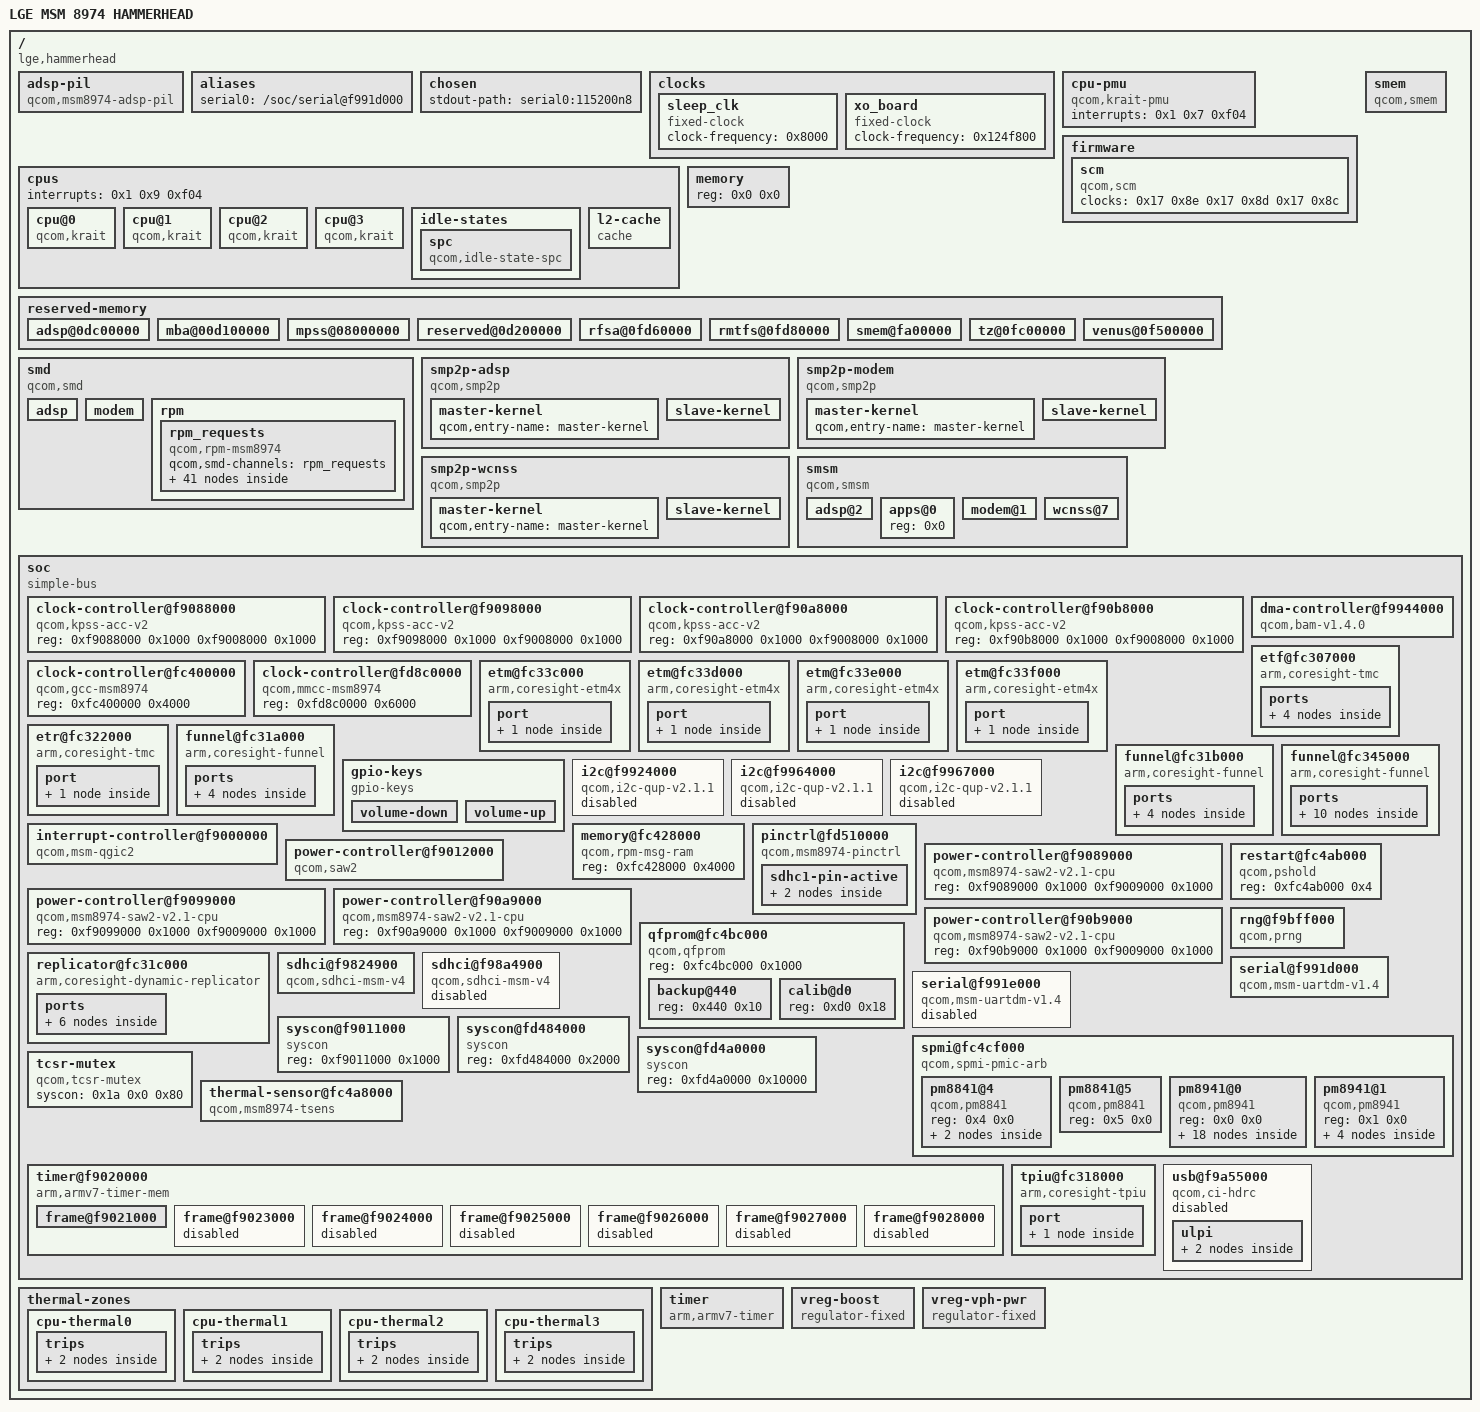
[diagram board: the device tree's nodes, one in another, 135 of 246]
/dts-v1/;

/ {
	#address-cells = <0x1>;
	#size-cells = <0x1>;
	compatible = "lge,hammerhead", "qcom,msm8974";
	interrupt-parent = <0x1>;
	model = "LGE MSM 8974 HAMMERHEAD";

	__symbols__ {
		CPU0 = "/cpus/cpu@0";
		CPU1 = "/cpus/cpu@1";
		CPU2 = "/cpus/cpu@2";
		CPU3 = "/cpus/cpu@3";
		CPU_SPC = "/cpus/idle-states/spc";
		L2 = "/cpus/l2-cache";
		acc0 = "/soc/clock-controller@f9088000";
		acc1 = "/soc/clock-controller@f9098000";
		acc2 = "/soc/clock-controller@f90a8000";
		acc3 = "/soc/clock-controller@f90b8000";
		adsp_region = "/reserved-memory/adsp@0dc00000";
		adsp_smp2p_in = "/smp2p-adsp/slave-kernel";
		adsp_smp2p_out = "/smp2p-adsp/master-kernel";
		adsp_smsm = "/smsm/adsp@2";
		apcs = "/soc/syscon@f9011000";
		apps_smsm = "/smsm/apps@0";
		blsp1_uart1 = "/soc/serial@f991d000";
		blsp1_uart2 = "/soc/serial@f991e000";
		blsp2_dma = "/soc/dma-controller@f9944000";
		blsp_i2c11 = "/soc/i2c@f9967000";
		blsp_i2c8 = "/soc/i2c@f9964000";
		boost_bypass_n_pin = "/soc/spmi@fc4cf000/pm8941@0/gpios@c000/boost-bypass";
		chg_otg = "/soc/spmi@fc4cf000/pm8941@0/charger@1000/otg-vbus";
		cpu_alert0 = "/thermal-zones/cpu-thermal0/trips/trip0";
		cpu_alert1 = "/thermal-zones/cpu-thermal1/trips/trip0";
		cpu_alert2 = "/thermal-zones/cpu-thermal2/trips/trip0";
		cpu_alert3 = "/thermal-zones/cpu-thermal3/trips/trip0";
		cpu_crit0 = "/thermal-zones/cpu-thermal0/trips/trip1";
		cpu_crit1 = "/thermal-zones/cpu-thermal1/trips/trip1";
		cpu_crit2 = "/thermal-zones/cpu-thermal2/trips/trip1";
		cpu_crit3 = "/thermal-zones/cpu-thermal3/trips/trip1";
		etf_in = "/soc/etf@fc307000/ports/port@1/endpoint";
		etf_out = "/soc/etf@fc307000/ports/port@0/endpoint";
		etm0_out = "/soc/etm@fc33c000/port/endpoint";
		etm1_out = "/soc/etm@fc33d000/port/endpoint";
		etm2_out = "/soc/etm@fc33e000/port/endpoint";
		etm3_out = "/soc/etm@fc33f000/port/endpoint";
		etr_in = "/soc/etr@fc322000/port/endpoint";
		funnel1_in5 = "/soc/funnel@fc31a000/ports/port@5/endpoint";
		funnel1_out = "/soc/funnel@fc31a000/ports/port@8/endpoint";
		gcc = "/soc/clock-controller@fc400000";
		gpio_keys_pin_a = "/soc/spmi@fc4cf000/pm8941@0/gpios@c000/gpio-keys-active";
		intc = "/soc/interrupt-controller@f9000000";
		kpss_in0 = "/soc/funnel@fc345000/ports/port@0/endpoint";
		kpss_in1 = "/soc/funnel@fc345000/ports/port@1/endpoint";
		kpss_in2 = "/soc/funnel@fc345000/ports/port@2/endpoint";
		kpss_in3 = "/soc/funnel@fc345000/ports/port@3/endpoint";
		kpss_out = "/soc/funnel@fc345000/ports/port@8/endpoint";
		merger_in1 = "/soc/funnel@fc31b000/ports/port@1/endpoint";
		merger_out = "/soc/funnel@fc31b000/ports/port@8/endpoint";
		mmcc = "/soc/clock-controller@fd8c0000";
		modem_smp2p_in = "/smp2p-modem/slave-kernel";
		modem_smp2p_out = "/smp2p-modem/master-kernel";
		modem_smsm = "/smsm/modem@1";
		msmgpio = "/soc/pinctrl@fd510000";
		otg = "/soc/usb@f9a55000";
		pm8841_0 = "/soc/spmi@fc4cf000/pm8841@4";
		pm8841_1 = "/soc/spmi@fc4cf000/pm8841@5";
		pm8841_mpps = "/soc/spmi@fc4cf000/pm8841@4/mpps@a000";
		pm8841_s1 = "/smd/rpm/rpm_requests/pm8841-regulators/s1";
		pm8841_s2 = "/smd/rpm/rpm_requests/pm8841-regulators/s2";
		pm8841_s3 = "/smd/rpm/rpm_requests/pm8841-regulators/s3";
		pm8841_s4 = "/smd/rpm/rpm_requests/pm8841-regulators/s4";
		pm8841_s5 = "/smd/rpm/rpm_requests/pm8841-regulators/s5";
		pm8841_s6 = "/smd/rpm/rpm_requests/pm8841-regulators/s6";
		pm8841_s7 = "/smd/rpm/rpm_requests/pm8841-regulators/s7";
		pm8841_s8 = "/smd/rpm/rpm_requests/pm8841-regulators/s8";
		pm8941_0 = "/soc/spmi@fc4cf000/pm8941@0";
		pm8941_1 = "/soc/spmi@fc4cf000/pm8941@1";
		pm8941_5v = "/soc/spmi@fc4cf000/pm8941@1/regulators/s4";
		pm8941_5vs1 = "/soc/spmi@fc4cf000/pm8941@1/regulators/5vs1";
		pm8941_gpios = "/soc/spmi@fc4cf000/pm8941@0/gpios@c000";
		pm8941_iadc = "/soc/spmi@fc4cf000/pm8941@0/iadc@3600";
		pm8941_l1 = "/smd/rpm/rpm_requests/pm8941-regulators/l1";
		pm8941_l10 = "/smd/rpm/rpm_requests/pm8941-regulators/l10";
		pm8941_l11 = "/smd/rpm/rpm_requests/pm8941-regulators/l11";
		pm8941_l12 = "/smd/rpm/rpm_requests/pm8941-regulators/l12";
		pm8941_l13 = "/smd/rpm/rpm_requests/pm8941-regulators/l13";
		pm8941_l14 = "/smd/rpm/rpm_requests/pm8941-regulators/l14";
		pm8941_l15 = "/smd/rpm/rpm_requests/pm8941-regulators/l15";
		pm8941_l16 = "/smd/rpm/rpm_requests/pm8941-regulators/l16";
		pm8941_l17 = "/smd/rpm/rpm_requests/pm8941-regulators/l17";
		pm8941_l18 = "/smd/rpm/rpm_requests/pm8941-regulators/l18";
		pm8941_l19 = "/smd/rpm/rpm_requests/pm8941-regulators/l19";
		pm8941_l2 = "/smd/rpm/rpm_requests/pm8941-regulators/l2";
		pm8941_l20 = "/smd/rpm/rpm_requests/pm8941-regulators/l20";
		pm8941_l21 = "/smd/rpm/rpm_requests/pm8941-regulators/l21";
		pm8941_l22 = "/smd/rpm/rpm_requests/pm8941-regulators/l22";
		pm8941_l23 = "/smd/rpm/rpm_requests/pm8941-regulators/l23";
		pm8941_l24 = "/smd/rpm/rpm_requests/pm8941-regulators/l24";
		pm8941_l3 = "/smd/rpm/rpm_requests/pm8941-regulators/l3";
		pm8941_l4 = "/smd/rpm/rpm_requests/pm8941-regulators/l4";
		pm8941_l5 = "/smd/rpm/rpm_requests/pm8941-regulators/l5";
		pm8941_l6 = "/smd/rpm/rpm_requests/pm8941-regulators/l6";
		pm8941_l7 = "/smd/rpm/rpm_requests/pm8941-regulators/l7";
		pm8941_l8 = "/smd/rpm/rpm_requests/pm8941-regulators/l8";
		pm8941_l9 = "/smd/rpm/rpm_requests/pm8941-regulators/l9";
		pm8941_lvs1 = "/smd/rpm/rpm_requests/pm8941-regulators/lvs1";
		pm8941_lvs2 = "/smd/rpm/rpm_requests/pm8941-regulators/lvs2";
		pm8941_lvs3 = "/smd/rpm/rpm_requests/pm8941-regulators/lvs3";
		pm8941_mpps = "/soc/spmi@fc4cf000/pm8941@0/mpps@a000";
		pm8941_s1 = "/smd/rpm/rpm_requests/pm8941-regulators/s1";
		pm8941_s2 = "/smd/rpm/rpm_requests/pm8941-regulators/s2";
		pm8941_s3 = "/smd/rpm/rpm_requests/pm8941-regulators/s3";
		pm8941_temp = "/soc/spmi@fc4cf000/pm8941@0/temp-alarm@2400";
		pm8941_vadc = "/soc/spmi@fc4cf000/pm8941@0/vadc@3100";
		pm8941_wled = "/soc/spmi@fc4cf000/pm8941@1/wled@d800";
		qfprom = "/soc/qfprom@fc4bc000";
		replicator_in = "/soc/replicator@fc31c000/ports/port@2/endpoint";
		replicator_out0 = "/soc/replicator@fc31c000/ports/port@0/endpoint";
		replicator_out1 = "/soc/replicator@fc31c000/ports/port@1/endpoint";
		rpm_msg_ram = "/soc/memory@fc428000";
		rpmcc = "/smd/rpm/rpm_requests/clock-controller";
		saw0 = "/soc/power-controller@f9089000";
		saw1 = "/soc/power-controller@f9099000";
		saw2 = "/soc/power-controller@f90a9000";
		saw3 = "/soc/power-controller@f90b9000";
		saw_l2 = "/soc/power-controller@f9012000";
		sdhc1_pin_a = "/soc/pinctrl@fd510000/sdhc1-pin-active";
		sleep_clk = "/clocks/sleep_clk";
		smbb = "/soc/spmi@fc4cf000/pm8941@0/charger@1000";
		smem_region = "/reserved-memory/smem@fa00000";
		soc = "/soc";
		spmi_bus = "/soc/spmi@fc4cf000";
		tcsr = "/soc/syscon@fd4a0000";
		tcsr_mutex = "/soc/tcsr-mutex";
		tcsr_mutex_block = "/soc/syscon@fd484000";
		tpiu_in = "/soc/tpiu@fc318000/port/endpoint";
		tsens = "/soc/thermal-sensor@fc4a8000";
		tsens_backup = "/soc/qfprom@fc4bc000/backup@440";
		tsens_calib = "/soc/qfprom@fc4bc000/calib@d0";
		usb_hs1_phy = "/soc/usb@f9a55000/ulpi/phy@a";
		usb_hs2_phy = "/soc/usb@f9a55000/ulpi/phy@b";
		usb_id = "/soc/spmi@fc4cf000/pm8941@0/misc@900";
		vreg_boost = "/vreg-boost";
		vreg_vph_pwr = "/vreg-vph-pwr";
		wcnss_smp2p_in = "/smp2p-wcnss/slave-kernel";
		wcnss_smp2p_out = "/smp2p-wcnss/master-kernel";
		wcnss_smsm = "/smsm/wcnss@7";
		xo_board = "/clocks/xo_board";
	};

	adsp-pil {
		clock-names = "xo";
		clocks = <0x10>;
		compatible = "qcom,msm8974-adsp-pil";
		cx-supply = <0xf>;
		interrupt-names = "wdog", "fatal", "ready", "handover", "stop-ack";
		interrupts-extended = <0x1 0x0 0xa2 0x1 0xe 0x0 0x1 0xe 0x1 0x1 0xe 0x2 0x1 0xe 0x3 0x1>;
		memory-region = <0x11>;
		qcom,smem-state-names = "stop";
		qcom,smem-states = <0x12 0x0>;
	};

	aliases {
		serial0 = "/soc/serial@f991d000";
	};

	chosen {
		stdout-path = "serial0:115200n8";
	};

	clocks {

		sleep_clk {
			#clock-cells = <0x0>;
			clock-frequency = <0x8000>;
			compatible = "fixed-clock";
			linux,phandle = <0x4b>;
			phandle = <0x4b>;
		};

		xo_board {
			#clock-cells = <0x0>;
			clock-frequency = <0x124f800>;
			compatible = "fixed-clock";
			linux,phandle = <0x10>;
			phandle = <0x10>;
		};
	};

	cpu-pmu {
		compatible = "qcom,krait-pmu";
		interrupts = <0x1 0x7 0xf04>;
	};

	cpus {
		#address-cells = <0x1>;
		#size-cells = <0x0>;
		interrupts = <0x1 0x9 0xf04>;

		cpu@0 {
			compatible = "qcom,krait";
			cpu-idle-states = <0x5>;
			device_type = "cpu";
			enable-method = "qcom,kpss-acc-v2";
			linux,phandle = <0x34>;
			next-level-cache = <0x2>;
			phandle = <0x34>;
			qcom,acc = <0x3>;
			qcom,saw = <0x4>;
			reg = <0x0>;
		};

		cpu@1 {
			compatible = "qcom,krait";
			cpu-idle-states = <0x5>;
			device_type = "cpu";
			enable-method = "qcom,kpss-acc-v2";
			linux,phandle = <0x36>;
			next-level-cache = <0x2>;
			phandle = <0x36>;
			qcom,acc = <0x6>;
			qcom,saw = <0x7>;
			reg = <0x1>;
		};

		cpu@2 {
			compatible = "qcom,krait";
			cpu-idle-states = <0x5>;
			device_type = "cpu";
			enable-method = "qcom,kpss-acc-v2";
			linux,phandle = <0x38>;
			next-level-cache = <0x2>;
			phandle = <0x38>;
			qcom,acc = <0x8>;
			qcom,saw = <0x9>;
			reg = <0x2>;
		};

		cpu@3 {
			compatible = "qcom,krait";
			cpu-idle-states = <0x5>;
			device_type = "cpu";
			enable-method = "qcom,kpss-acc-v2";
			linux,phandle = <0x3a>;
			next-level-cache = <0x2>;
			phandle = <0x3a>;
			qcom,acc = <0xa>;
			qcom,saw = <0xb>;
			reg = <0x3>;
		};

		idle-states {

			spc {
				compatible = "qcom,idle-state-spc", "arm,idle-state";
				entry-latency-us = <0x96>;
				exit-latency-us = <0xc8>;
				linux,phandle = <0x5>;
				min-residency-us = <0x7d0>;
				phandle = <0x5>;
			};
		};

		l2-cache {
			cache-level = <0x2>;
			compatible = "cache";
			linux,phandle = <0x2>;
			phandle = <0x2>;
			qcom,saw = <0xc>;
		};
	};

	firmware {

		scm {
			clock-names = "core", "bus", "iface";
			clocks = <0x17 0x8e 0x17 0x8d 0x17 0x8c>;
			compatible = "qcom,scm";
		};
	};

	memory {
		device_type = "memory";
		reg = <0x0 0x0>;
	};

	reserved-memory {
		#address-cells = <0x1>;
		#size-cells = <0x1>;
		ranges;

		adsp@0dc00000 {
			linux,phandle = <0x11>;
			no-map;
			phandle = <0x11>;
			reg = <0xdc00000 0x1900000>;
		};

		mba@00d100000 {
			no-map;
			reg = <0xd100000 0x100000>;
		};

		mpss@08000000 {
			no-map;
			reg = <0x8000000 0x5100000>;
		};

		reserved@0d200000 {
			no-map;
			reg = <0xd200000 0xa00000>;
		};

		rfsa@0fd60000 {
			no-map;
			reg = <0xfd60000 0x20000>;
		};

		rmtfs@0fd80000 {
			no-map;
			reg = <0xfd80000 0x180000>;
		};

		smem@fa00000 {
			linux,phandle = <0x13>;
			no-map;
			phandle = <0x13>;
			reg = <0xfa00000 0x200000>;
		};

		tz@0fc00000 {
			no-map;
			reg = <0xfc00000 0x160000>;
		};

		venus@0f500000 {
			no-map;
			reg = <0xf500000 0x500000>;
		};
	};

	smd {
		compatible = "qcom,smd";

		adsp {
			interrupts = <0x0 0x9c 0x1>;
			qcom,ipc = <0x16 0x8 0x8>;
			qcom,smd-edge = <0x1>;
		};

		modem {
			interrupts = <0x0 0x19 0x1>;
			qcom,ipc = <0x16 0x8 0xc>;
			qcom,smd-edge = <0x0>;
		};

		rpm {
			interrupts = <0x0 0xa8 0x1>;
			qcom,ipc = <0x16 0x8 0x0>;
			qcom,smd-edge = <0xf>;

			rpm_requests {
				compatible = "qcom,rpm-msm8974";
				qcom,smd-channels = "rpm_requests";

				clock-controller {
					#clock-cells = <0x1>;
					compatible = "qcom,rpmcc-msm8974", "qcom,rpmcc";
					linux,phandle = <0x23>;
					phandle = <0x23>;
				};

				pm8841-regulators {
					compatible = "qcom,rpm-pm8841-regulators";

					s1 {
						linux,phandle = <0x6c>;
						phandle = <0x6c>;
						regulator-max-microvolt = <0x100590>;
						regulator-min-microvolt = <0xa4cb8>;
					};

					s2 {
						linux,phandle = <0xf>;
						phandle = <0xf>;
						regulator-max-microvolt = <0x100590>;
						regulator-min-microvolt = <0x7a120>;
					};

					s3 {
						linux,phandle = <0x6d>;
						phandle = <0x6d>;
						regulator-max-microvolt = <0x100590>;
						regulator-min-microvolt = <0x100590>;
					};

					s4 {
						linux,phandle = <0x6e>;
						phandle = <0x6e>;
						regulator-max-microvolt = <0xdbba0>;
						regulator-min-microvolt = <0xc6f98>;
					};

					s5 {
						linux,phandle = <0x6f>;
						phandle = <0x6f>;
					};

					s6 {
						linux,phandle = <0x70>;
						phandle = <0x70>;
					};

					s7 {
						linux,phandle = <0x71>;
						phandle = <0x71>;
					};

					s8 {
						linux,phandle = <0x72>;
						phandle = <0x72>;
					};
				};

				pm8941-regulators {
					compatible = "qcom,rpm-pm8941-regulators";
					vdd_l13_l20_l23_l24-supply = <0x41>;
					vdd_l1_l3-supply = <0x3e>;
					vdd_l21-supply = <0x41>;
					vdd_l2_lvs1_2_3-supply = <0x1c>;
					vdd_l4_l11-supply = <0x3e>;
					vdd_l5_l7-supply = <0x3f>;
					vdd_l6_l12_l14_l15-supply = <0x3f>;
					vdd_l8_l16_l18_l19-supply = <0x40>;
					vdd_l9_l10_l17_l22-supply = <0x41>;

					l1 {
						linux,phandle = <0x73>;
						phandle = <0x73>;
						regulator-always-on;
						regulator-boot-on;
						regulator-max-microvolt = <0x12b128>;
						regulator-min-microvolt = <0x12b128>;
					};

					l10 {
						linux,phandle = <0x7c>;
						phandle = <0x7c>;
						regulator-max-microvolt = <0x2d0370>;
						regulator-min-microvolt = <0x1b7740>;
					};

					l11 {
						linux,phandle = <0x7d>;
						phandle = <0x7d>;
						regulator-max-microvolt = <0x13d620>;
						regulator-min-microvolt = <0x13d620>;
					};

					l12 {
						linux,phandle = <0x7e>;
						phandle = <0x7e>;
						regulator-always-on;
						regulator-boot-on;
						regulator-max-microvolt = <0x1b7740>;
						regulator-min-microvolt = <0x1b7740>;
					};

					l13 {
						linux,phandle = <0x7f>;
						phandle = <0x7f>;
						regulator-boot-on;
						regulator-max-microvolt = <0x2d0370>;
						regulator-min-microvolt = <0x1b7740>;
					};

					l14 {
						linux,phandle = <0x80>;
						phandle = <0x80>;
						regulator-max-microvolt = <0x1b7740>;
						regulator-min-microvolt = <0x1b7740>;
					};

					l15 {
						linux,phandle = <0x81>;
						phandle = <0x81>;
						regulator-max-microvolt = <0x1f47d0>;
						regulator-min-microvolt = <0x1f47d0>;
					};

					l16 {
						linux,phandle = <0x82>;
						phandle = <0x82>;
						regulator-max-microvolt = <0x2932e0>;
						regulator-min-microvolt = <0x2932e0>;
					};

					l17 {
						linux,phandle = <0x83>;
						phandle = <0x83>;
						regulator-max-microvolt = <0x2b7cd0>;
						regulator-min-microvolt = <0x2b7cd0>;
					};

					l18 {
						linux,phandle = <0x84>;
						phandle = <0x84>;
						regulator-max-microvolt = <0x2b7cd0>;
						regulator-min-microvolt = <0x2b7cd0>;
					};

					l19 {
						linux,phandle = <0x85>;
						phandle = <0x85>;
						regulator-max-microvolt = <0x325aa0>;
						regulator-min-microvolt = <0x2dc6c0>;
					};

					l2 {
						linux,phandle = <0x74>;
						phandle = <0x74>;
						regulator-max-microvolt = <0x124f80>;
						regulator-min-microvolt = <0x124f80>;
					};

					l20 {
						linux,phandle = <0x1b>;
						phandle = <0x1b>;
						regulator-allow-set-load;
						regulator-boot-on;
						regulator-max-microvolt = <0x2d0370>;
						regulator-min-microvolt = <0x2d0370>;
						regulator-system-load = <0x30d40>;
					};

					l21 {
						linux,phandle = <0x86>;
						phandle = <0x86>;
						regulator-boot-on;
						regulator-max-microvolt = <0x2d0370>;
						regulator-min-microvolt = <0x2d0370>;
					};

					l22 {
						linux,phandle = <0x87>;
						phandle = <0x87>;
						regulator-max-microvolt = <0x325aa0>;
						regulator-min-microvolt = <0x2dc6c0>;
					};

					l23 {
						linux,phandle = <0x88>;
						phandle = <0x88>;
						regulator-max-microvolt = <0x2dc6c0>;
						regulator-min-microvolt = <0x2dc6c0>;
					};

					l24 {
						linux,phandle = <0x89>;
						phandle = <0x89>;
						regulator-boot-on;
						regulator-max-microvolt = <0x2eebb8>;
						regulator-min-microvolt = <0x2eebb8>;
					};

					l3 {
						linux,phandle = <0x75>;
						phandle = <0x75>;
						regulator-max-microvolt = <0x12b128>;
						regulator-min-microvolt = <0x12b128>;
					};

					l4 {
						linux,phandle = <0x76>;
						phandle = <0x76>;
						regulator-max-microvolt = <0x12b128>;
						regulator-min-microvolt = <0x12b128>;
					};

					l5 {
						linux,phandle = <0x77>;
						phandle = <0x77>;
						regulator-max-microvolt = <0x1b7740>;
						regulator-min-microvolt = <0x1b7740>;
					};

					l6 {
						linux,phandle = <0x78>;
						phandle = <0x78>;
						regulator-boot-on;
						regulator-max-microvolt = <0x1b7740>;
						regulator-min-microvolt = <0x1b7740>;
					};

					l7 {
						linux,phandle = <0x79>;
						phandle = <0x79>;
						regulator-boot-on;
						regulator-max-microvolt = <0x1b7740>;
						regulator-min-microvolt = <0x1b7740>;
					};

					l8 {
						linux,phandle = <0x7a>;
						phandle = <0x7a>;
						regulator-max-microvolt = <0x1b7740>;
						regulator-min-microvolt = <0x1b7740>;
					};

					l9 {
						linux,phandle = <0x7b>;
						phandle = <0x7b>;
						regulator-max-microvolt = <0x2d0370>;
						regulator-min-microvolt = <0x1b7740>;
					};

					lvs1 {
						linux,phandle = <0x8a>;
						phandle = <0x8a>;
					};

					lvs2 {
						linux,phandle = <0x8b>;
						phandle = <0x8b>;
					};

					lvs3 {
						linux,phandle = <0x8c>;
						phandle = <0x8c>;
					};

					s1 {
						linux,phandle = <0x3e>;
						phandle = <0x3e>;
						regulator-always-on;
						regulator-boot-on;
						regulator-max-microvolt = <0x13d620>;
						regulator-min-microvolt = <0x13d620>;
					};

					s2 {
						linux,phandle = <0x3f>;
						phandle = <0x3f>;
						regulator-boot-on;
						regulator-max-microvolt = <0x20ce70>;
						regulator-min-microvolt = <0x20ce70>;
					};

					s3 {
						linux,phandle = <0x1c>;
						phandle = <0x1c>;
						regulator-always-on;
						regulator-boot-on;
						regulator-max-microvolt = <0x1b7740>;
						regulator-min-microvolt = <0x1b7740>;
					};
				};
			};
		};
	};

	smem {
		compatible = "qcom,smem";
		hwlocks = <0x15 0x3>;
		memory-region = <0x13>;
		qcom,rpm-msg-ram = <0x14>;
	};

	smp2p-adsp {
		compatible = "qcom,smp2p";
		interrupt-parent = <0x1>;
		interrupts = <0x0 0x9e 0x1>;
		qcom,ipc = <0x16 0x8 0xa>;
		qcom,local-pid = <0x0>;
		qcom,remote-pid = <0x2>;
		qcom,smem = <0x1bb 0x1ad>;

		master-kernel {
			#qcom,smem-state-cells = <0x1>;
			linux,phandle = <0x12>;
			phandle = <0x12>;
			qcom,entry-name = "master-kernel";
		};

		slave-kernel {
			#interrupt-cells = <0x2>;
			interrupt-controller;
			linux,phandle = <0xe>;
			phandle = <0xe>;
			qcom,entry-name = "slave-kernel";
		};
	};

	smp2p-modem {
		compatible = "qcom,smp2p";
		interrupt-parent = <0x1>;
		interrupts = <0x0 0x1b 0x1>;
		qcom,ipc = <0x16 0x8 0xe>;
		qcom,local-pid = <0x0>;
		qcom,remote-pid = <0x1>;
		qcom,smem = <0x1b3 0x1ac>;

		master-kernel {
			#qcom,smem-state-cells = <0x1>;
			linux,phandle = <0x4c>;
			phandle = <0x4c>;
			qcom,entry-name = "master-kernel";
		};

		slave-kernel {
			#interrupt-cells = <0x2>;
			interrupt-controller;
			linux,phandle = <0x4d>;
			phandle = <0x4d>;
			qcom,entry-name = "slave-kernel";
		};
	};

	smp2p-wcnss {
		compatible = "qcom,smp2p";
		interrupt-parent = <0x1>;
		interrupts = <0x0 0x8f 0x1>;
		qcom,ipc = <0x16 0x8 0x12>;
		qcom,local-pid = <0x0>;
		qcom,remote-pid = <0x4>;
		qcom,smem = <0x1c3 0x1af>;

		master-kernel {
			#qcom,smem-state-cells = <0x1>;
			linux,phandle = <0x4e>;
			phandle = <0x4e>;
			qcom,entry-name = "master-kernel";
		};

		slave-kernel {
			#interrupt-cells = <0x2>;
			interrupt-controller;
			linux,phandle = <0x4f>;
			phandle = <0x4f>;
			qcom,entry-name = "slave-kernel";
		};
	};

	smsm {
		#address-cells = <0x1>;
		#size-cells = <0x0>;
		compatible = "qcom,smsm";
		qcom,ipc-1 = <0x16 0x8 0xd>;
		qcom,ipc-2 = <0x16 0x8 0x9>;
		qcom,ipc-3 = <0x16 0x8 0x13>;

		adsp@2 {
			#interrupt-cells = <0x2>;
			interrupt-controller;
			interrupts = <0x0 0x9d 0x1>;
			linux,phandle = <0x52>;
			phandle = <0x52>;
			reg = <0x2>;
		};

		apps@0 {
			#qcom,smem-state-cells = <0x1>;
			linux,phandle = <0x50>;
			phandle = <0x50>;
			reg = <0x0>;
		};

		modem@1 {
			#interrupt-cells = <0x2>;
			interrupt-controller;
			interrupts = <0x0 0x1a 0x1>;
			linux,phandle = <0x51>;
			phandle = <0x51>;
			reg = <0x1>;
		};

		wcnss@7 {
			#interrupt-cells = <0x2>;
			interrupt-controller;
			interrupts = <0x0 0x90 0x1>;
			linux,phandle = <0x53>;
			phandle = <0x53>;
			reg = <0x7>;
		};
	};

	soc {
		#address-cells = <0x1>;
		#size-cells = <0x1>;
		compatible = "simple-bus";
		linux,phandle = <0x54>;
		phandle = <0x54>;
		ranges;

		clock-controller@f9088000 {
			compatible = "qcom,kpss-acc-v2";
			linux,phandle = <0x3>;
			phandle = <0x3>;
			reg = <0xf9088000 0x1000 0xf9008000 0x1000>;
		};

		clock-controller@f9098000 {
			compatible = "qcom,kpss-acc-v2";
			linux,phandle = <0x6>;
			phandle = <0x6>;
			reg = <0xf9098000 0x1000 0xf9008000 0x1000>;
		};

		clock-controller@f90a8000 {
			compatible = "qcom,kpss-acc-v2";
			linux,phandle = <0x8>;
			phandle = <0x8>;
			reg = <0xf90a8000 0x1000 0xf9008000 0x1000>;
		};

		clock-controller@f90b8000 {
			compatible = "qcom,kpss-acc-v2";
			linux,phandle = <0xa>;
			phandle = <0xa>;
			reg = <0xf90b8000 0x1000 0xf9008000 0x1000>;
		};

		clock-controller@fc400000 {
			#clock-cells = <0x1>;
			#power-domain-cells = <0x1>;
			#reset-cells = <0x1>;
			compatible = "qcom,gcc-msm8974";
			linux,phandle = <0x17>;
			phandle = <0x17>;
			reg = <0xfc400000 0x4000>;
		};

		clock-controller@fd8c0000 {
			#clock-cells = <0x1>;
			#power-domain-cells = <0x1>;
			#reset-cells = <0x1>;
			compatible = "qcom,mmcc-msm8974";
			linux,phandle = <0x57>;
			phandle = <0x57>;
			reg = <0xfd8c0000 0x6000>;
		};

		dma-controller@f9944000 {
			#dma-cells = <0x1>;
			clock-names = "bam_clk";
			clocks = <0x17 0x71>;
			compatible = "qcom,bam-v1.4.0";
			interrupts = <0x0 0xef 0x4>;
			linux,phandle = <0x1f>;
			phandle = <0x1f>;
			qcom,ee = <0x0>;
			reg = <0xf9944000 0x19000>;
		};

		etf@fc307000 {
			clock-names = "apb_pclk", "atclk";
			clocks = <0x23 0x8 0x23 0x9>;
			compatible = "arm,coresight-tmc", "arm,primecell";
			reg = <0xfc307000 0x1000>;

			ports {
				#address-cells = <0x1>;
				#size-cells = <0x0>;

				port@0 {
					reg = <0x0>;

					endpoint {
						linux,phandle = <0x28>;
						phandle = <0x28>;
						remote-endpoint = <0x29>;
					};
				};

				port@1 {
					reg = <0x0>;

					endpoint {
						linux,phandle = <0x2c>;
						phandle = <0x2c>;
						remote-endpoint = <0x2a>;
						slave-mode;
					};
				};
			};
		};

		etm@fc33c000 {
			clock-names = "apb_pclk", "atclk";
			clocks = <0x23 0x8 0x23 0x9>;
			compatible = "arm,coresight-etm4x", "arm,primecell";
			cpu = <0x34>;
			reg = <0xfc33c000 0x1000>;

			port {

				endpoint {
					linux,phandle = <0x2f>;
					phandle = <0x2f>;
					remote-endpoint = <0x35>;
				};
			};
		};

		etm@fc33d000 {
			clock-names = "apb_pclk", "atclk";
			clocks = <0x23 0x8 0x23 0x9>;
			compatible = "arm,coresight-etm4x", "arm,primecell";
			cpu = <0x36>;
			reg = <0xfc33d000 0x1000>;

			port {

				endpoint {
					linux,phandle = <0x30>;
					phandle = <0x30>;
					remote-endpoint = <0x37>;
				};
			};
		};

		etm@fc33e000 {
			clock-names = "apb_pclk", "atclk";
			clocks = <0x23 0x8 0x23 0x9>;
			compatible = "arm,coresight-etm4x", "arm,primecell";
			cpu = <0x38>;
			reg = <0xfc33e000 0x1000>;

			port {

				endpoint {
					linux,phandle = <0x31>;
					phandle = <0x31>;
					remote-endpoint = <0x39>;
				};
			};
		};

		etm@fc33f000 {
			clock-names = "apb_pclk", "atclk";
			clocks = <0x23 0x8 0x23 0x9>;
			compatible = "arm,coresight-etm4x", "arm,primecell";
			cpu = <0x3a>;
			reg = <0xfc33f000 0x1000>;

			port {

				endpoint {
					linux,phandle = <0x32>;
					phandle = <0x32>;
					remote-endpoint = <0x3b>;
				};
			};
		};

		etr@fc322000 {
			clock-names = "apb_pclk", "atclk";
			clocks = <0x23 0x8 0x23 0x9>;
			compatible = "arm,coresight-tmc", "arm,primecell";
			reg = <0xfc322000 0x1000>;

			port {

				endpoint {
					linux,phandle = <0x26>;
					phandle = <0x26>;
					remote-endpoint = <0x24>;
					slave-mode;
				};
			};
		};

		funnel@fc31a000 {
			clock-names = "apb_pclk", "atclk";
			clocks = <0x23 0x8 0x23 0x9>;
			compatible = "arm,coresight-funnel", "arm,primecell";
			reg = <0xfc31a000 0x1000>;

			ports {
				#address-cells = <0x1>;
				#size-cells = <0x0>;

				port@5 {
					reg = <0x5>;

					endpoint {
						linux,phandle = <0x33>;
						phandle = <0x33>;
						remote-endpoint = <0x2d>;
						slave-mode;
					};
				};

				port@8 {
					reg = <0x0>;

					endpoint {
						linux,phandle = <0x2b>;
						phandle = <0x2b>;
						remote-endpoint = <0x2e>;
					};
				};
			};
		};

		funnel@fc31b000 {
			clock-names = "apb_pclk", "atclk";
			clocks = <0x23 0x8 0x23 0x9>;
			compatible = "arm,coresight-funnel", "arm,primecell";
			reg = <0xfc31b000 0x1000>;

			ports {
				#address-cells = <0x1>;
				#size-cells = <0x0>;

				port@1 {
					reg = <0x1>;

					endpoint {
						linux,phandle = <0x2e>;
						phandle = <0x2e>;
						remote-endpoint = <0x2b>;
						slave-mode;
					};
				};

				port@8 {
					reg = <0x0>;

					endpoint {
						linux,phandle = <0x2a>;
						phandle = <0x2a>;
						remote-endpoint = <0x2c>;
					};
				};
			};
		};

		funnel@fc345000 {
			clock-names = "apb_pclk", "atclk";
			clocks = <0x23 0x8 0x23 0x9>;
			compatible = "arm,coresight-funnel", "arm,primecell";
			reg = <0xfc345000 0x1000>;

			ports {
				#address-cells = <0x1>;
				#size-cells = <0x0>;

				port@0 {
					reg = <0x0>;

					endpoint {
						linux,phandle = <0x35>;
						phandle = <0x35>;
						remote-endpoint = <0x2f>;
						slave-mode;
					};
				};

				port@1 {
					reg = <0x1>;

					endpoint {
						linux,phandle = <0x37>;
						phandle = <0x37>;
						remote-endpoint = <0x30>;
						slave-mode;
					};
				};

				port@2 {
					reg = <0x2>;

					endpoint {
						linux,phandle = <0x39>;
						phandle = <0x39>;
						remote-endpoint = <0x31>;
						slave-mode;
					};
				};

				port@3 {
					reg = <0x3>;

					endpoint {
						linux,phandle = <0x3b>;
						phandle = <0x3b>;
						remote-endpoint = <0x32>;
						slave-mode;
					};
				};

				port@8 {
					reg = <0x0>;

					endpoint {
						linux,phandle = <0x2d>;
						phandle = <0x2d>;
						remote-endpoint = <0x33>;
					};
				};
			};
		};

		gpio-keys {
			compatible = "gpio-keys";
			input-name = "gpio-keys";
			pinctrl-0 = <0x3c>;
			pinctrl-names = "default";

			volume-down {
				gpios = <0x3d 0x3 0x1>;
				label = "volume_down";
				linux,code = <0x72>;
				linux,input-type = <0x1>;
			};

			volume-up {
				gpios = <0x3d 0x2 0x1>;
				label = "volume_up";
				linux,code = <0x73>;
				linux,input-type = <0x1>;
			};
		};

		i2c@f9924000 {
			#address-cells = <0x1>;
			#size-cells = <0x0>;
			clock-names = "core", "iface";
			clocks = <0x17 0x5b 0x17 0x57>;
			compatible = "qcom,i2c-qup-v2.1.1";
			interrupts = <0x0 0x60 0x0>;
			reg = <0xf9924000 0x1000>;
			status = "disabled";
		};

		i2c@f9964000 {
			#address-cells = <0x1>;
			#size-cells = <0x0>;
			clock-names = "core", "iface";
			clocks = <0x17 0x75 0x17 0x71>;
			compatible = "qcom,i2c-qup-v2.1.1";
			interrupts = <0x0 0x66 0x0>;
			linux,phandle = <0x5d>;
			phandle = <0x5d>;
			reg = <0xf9964000 0x1000>;
			status = "disabled";
		};

		i2c@f9967000 {
			#address-cells = <0x1>;
			#size-cells = <0x0>;
			clock-names = "core", "iface";
			clocks = <0x17 0x7b 0x17 0x71>;
			compatible = "qcom,i2c-qup-v2.1.1";
			dma-names = "tx", "rx";
			dmas = <0x1f 0x14 0x1f 0x15>;
			interrupts = <0x0 0x69 0x0>;
			linux,phandle = <0x5e>;
			phandle = <0x5e>;
			reg = <0xf9967000 0x1000>;
			status = "disabled";
		};

		interrupt-controller@f9000000 {
			#interrupt-cells = <0x3>;
			compatible = "qcom,msm-qgic2";
			interrupt-controller;
			linux,phandle = <0x1>;
			phandle = <0x1>;
			reg = <0xf9000000 0x1000 0xf9002000 0x1000>;
		};

		memory@fc428000 {
			compatible = "qcom,rpm-msg-ram";
			linux,phandle = <0x14>;
			phandle = <0x14>;
			reg = <0xfc428000 0x4000>;
		};

		pinctrl@fd510000 {
			#gpio-cells = <0x2>;
			#interrupt-cells = <0x2>;
			compatible = "qcom,msm8974-pinctrl";
			gpio-controller;
			interrupt-controller;
			interrupts = <0x0 0xd0 0x0>;
			linux,phandle = <0x5c>;
			phandle = <0x5c>;
			reg = <0xfd510000 0x4000>;

			sdhc1-pin-active {
				linux,phandle = <0x1d>;
				phandle = <0x1d>;

				clk {
					bias-disable;
					drive-strength = <0x10>;
					pins = "sdc1_clk";
				};

				cmd-data {
					bias-pull-up;
					drive-strength = <0xa>;
					pins = "sdc1_cmd", "sdc1_data";
				};
			};
		};

		power-controller@f9012000 {
			compatible = "qcom,saw2";
			linux,phandle = <0xc>;
			phandle = <0xc>;
			reg = <0xf9012000 0x1000>;
			regulator;
		};

		power-controller@f9089000 {
			compatible = "qcom,msm8974-saw2-v2.1-cpu", "qcom,saw2";
			linux,phandle = <0x4>;
			phandle = <0x4>;
			reg = <0xf9089000 0x1000 0xf9009000 0x1000>;
		};

		power-controller@f9099000 {
			compatible = "qcom,msm8974-saw2-v2.1-cpu", "qcom,saw2";
			linux,phandle = <0x7>;
			phandle = <0x7>;
			reg = <0xf9099000 0x1000 0xf9009000 0x1000>;
		};

		power-controller@f90a9000 {
			compatible = "qcom,msm8974-saw2-v2.1-cpu", "qcom,saw2";
			linux,phandle = <0x9>;
			phandle = <0x9>;
			reg = <0xf90a9000 0x1000 0xf9009000 0x1000>;
		};

		power-controller@f90b9000 {
			compatible = "qcom,msm8974-saw2-v2.1-cpu", "qcom,saw2";
			linux,phandle = <0xb>;
			phandle = <0xb>;
			reg = <0xf90b9000 0x1000 0xf9009000 0x1000>;
		};

		qfprom@fc4bc000 {
			#address-cells = <0x1>;
			#size-cells = <0x1>;
			compatible = "qcom,qfprom";
			linux,phandle = <0x55>;
			phandle = <0x55>;
			reg = <0xfc4bc000 0x1000>;

			backup@440 {
				linux,phandle = <0x19>;
				phandle = <0x19>;
				reg = <0x440 0x10>;
			};

			calib@d0 {
				linux,phandle = <0x18>;
				phandle = <0x18>;
				reg = <0xd0 0x18>;
			};
		};

		replicator@fc31c000 {
			clock-names = "apb_pclk", "atclk";
			clocks = <0x23 0x8 0x23 0x9>;
			compatible = "arm,coresight-dynamic-replicator", "arm,primecell";
			reg = <0xfc31c000 0x1000>;

			ports {
				#address-cells = <0x1>;
				#size-cells = <0x0>;

				port@0 {
					reg = <0x0>;

					endpoint {
						linux,phandle = <0x24>;
						phandle = <0x24>;
						remote-endpoint = <0x26>;
					};
				};

				port@1 {
					reg = <0x1>;

					endpoint {
						linux,phandle = <0x25>;
						phandle = <0x25>;
						remote-endpoint = <0x27>;
					};
				};

				port@2 {
					reg = <0x0>;

					endpoint {
						linux,phandle = <0x29>;
						phandle = <0x29>;
						remote-endpoint = <0x28>;
						slave-mode;
					};
				};
			};
		};

		restart@fc4ab000 {
			compatible = "qcom,pshold";
			reg = <0xfc4ab000 0x4>;
		};

		rng@f9bff000 {
			clock-names = "core";
			clocks = <0x17 0xc3>;
			compatible = "qcom,prng";
			reg = <0xf9bff000 0x200>;
		};

		sdhci@f9824900 {
			bus-width = <0x8>;
			clock-names = "core", "iface", "xo";
			clocks = <0x17 0xd8 0x17 0xd7 0x10>;
			compatible = "qcom,sdhci-msm-v4";
			interrupt-names = "hc_irq", "pwr_irq";
			interrupts = <0x0 0x7b 0x0 0x0 0x8a 0x0>;
			non-removable;
			pinctrl-0 = <0x1d>;
			pinctrl-names = "default";
			reg = <0xf9824900 0x11c 0xf9824000 0x800>;
			reg-names = "hc_mem", "core_mem";
			status = "ok";
			vmmc-supply = <0x1b>;
			vqmmc-supply = <0x1c>;
		};

		sdhci@f98a4900 {
			clock-names = "core", "iface", "xo";
			clocks = <0x17 0xdb 0x17 0xda 0x10>;
			compatible = "qcom,sdhci-msm-v4";
			interrupt-names = "hc_irq", "pwr_irq";
			interrupts = <0x0 0x7d 0x0 0x0 0xdd 0x0>;
			reg = <0xf98a4900 0x11c 0xf98a4000 0x800>;
			reg-names = "hc_mem", "core_mem";
			status = "disabled";
		};

		serial@f991d000 {
			clock-names = "core", "iface";
			clocks = <0x17 0x65 0x17 0x57>;
			compatible = "qcom,msm-uartdm-v1.4", "qcom,msm-uartdm";
			interrupts = <0x0 0x6b 0x0>;
			linux,phandle = <0x58>;
			phandle = <0x58>;
			reg = <0xf991d000 0x1000>;
			status = "ok";
		};

		serial@f991e000 {
			clock-names = "core", "iface";
			clocks = <0x17 0x67 0x17 0x57>;
			compatible = "qcom,msm-uartdm-v1.4", "qcom,msm-uartdm";
			interrupts = <0x0 0x6c 0x0>;
			linux,phandle = <0x59>;
			phandle = <0x59>;
			reg = <0xf991e000 0x1000>;
			status = "disabled";
		};

		spmi@fc4cf000 {
			#address-cells = <0x2>;
			#interrupt-cells = <0x4>;
			#size-cells = <0x0>;
			compatible = "qcom,spmi-pmic-arb";
			interrupt-controller;
			interrupt-names = "periph_irq";
			interrupts = <0x0 0xbe 0x0>;
			linux,phandle = <0x5f>;
			phandle = <0x5f>;
			qcom,channel = <0x0>;
			qcom,ee = <0x0>;
			reg = <0xfc4cf000 0x1000 0xfc4cb000 0x1000 0xfc4ca000 0x1000>;
			reg-names = "core", "intr", "cnfg";

			pm8841@4 {
				#address-cells = <0x1>;
				#size-cells = <0x0>;
				compatible = "qcom,pm8841", "qcom,spmi-pmic";
				linux,phandle = <0x60>;
				phandle = <0x60>;
				reg = <0x4 0x0>;

				mpps@a000 {
					#gpio-cells = <0x2>;
					compatible = "qcom,pm8841-mpp", "qcom,spmi-mpp";
					gpio-controller;
					interrupts = <0x4 0xa0 0x0 0x0 0x4 0xa1 0x0 0x0 0x4 0xa2 0x0 0x0 0x4 0xa3 0x0 0x0>;
					linux,phandle = <0x61>;
					phandle = <0x61>;
					reg = <0xa000>;
				};

				temp-alarm@2400 {
					compatible = "qcom,spmi-temp-alarm";
					interrupts = <0x4 0x24 0x0 0x1>;
					reg = <0x2400>;
				};
			};

			pm8841@5 {
				#address-cells = <0x1>;
				#size-cells = <0x0>;
				compatible = "qcom,pm8841", "qcom,spmi-pmic";
				linux,phandle = <0x62>;
				phandle = <0x62>;
				reg = <0x5 0x0>;
			};

			pm8941@0 {
				#address-cells = <0x1>;
				#size-cells = <0x0>;
				compatible = "qcom,pm8941", "qcom,spmi-pmic";
				linux,phandle = <0x63>;
				phandle = <0x63>;
				reg = <0x0 0x0>;

				charger@1000 {
					compatible = "qcom,pm8941-charger";
					interrupt-names = "chg-done", "chg-fast", "chg-trkl", "bat-temp-ok", "bat-present", "chg-gone", "usb-valid", "dc-valid";
					interrupts = <0x0 0x10 0x7 0x3 0x0 0x10 0x5 0x3 0x0 0x10 0x4 0x3 0x0 0x12 0x1 0x3 0x0 0x12 0x0 0x3 0x0 0x13 0x2 0x3 0x0 0x13 0x1 0x3 0x0 0x14 0x1 0x3>;
					linux,phandle = <0x65>;
					phandle = <0x65>;
					reg = <0x1000>;
					usb-otg-in-supply = <0x20>;

					otg-vbus {
						linux,phandle = <0x66>;
						phandle = <0x66>;
					};
				};

				coincell@2800 {
					compatible = "qcom,pm8941-coincell";
					reg = <0x2800>;
					status = "disabled";
				};

				gpios@c000 {
					#gpio-cells = <0x2>;
					compatible = "qcom,pm8941-gpio", "qcom,spmi-gpio";
					gpio-controller;
					interrupts = <0x0 0xc0 0x0 0x0 0x0 0xc1 0x0 0x0 0x0 0xc2 0x0 0x0 0x0 0xc3 0x0 0x0 0x0 0xc4 0x0 0x0 0x0 0xc5 0x0 0x0 0x0 0xc6 0x0 0x0 0x0 0xc7 0x0 0x0 0x0 0xc8 0x0 0x0 0x0 0xc9 0x0 0x0 0x0 0xca 0x0 0x0 0x0 0xcb 0x0 0x0 0x0 0xcc 0x0 0x0 0x0 0xcd 0x0 0x0 0x0 0xce 0x0 0x0 0x0 0xcf 0x0 0x0 0x0 0xd0 0x0 0x0 0x0 0xd1 0x0 0x0 0x0 0xd2 0x0 0x0 0x0 0xd3 0x0 0x0 0x0 0xd4 0x0 0x0 0x0 0xd5 0x0 0x0 0x0 0xd6 0x0 0x0 0x0 0xd7 0x0 0x0 0x0 0xd8 0x0 0x0 0x0 0xd9 0x0 0x0 0x0 0xda 0x0 0x0 0x0 0xdb 0x0 0x0 0x0 0xdc 0x0 0x0 0x0 0xdd 0x0 0x0 0x0 0xde 0x0 0x0 0x0 0xdf 0x0 0x0 0x0 0xe0 0x0 0x0 0x0 0xe1 0x0 0x0 0x0 0xe2 0x0 0x0 0x0 0xe3 0x0 0x0>;
					linux,phandle = <0x3d>;
					phandle = <0x3d>;
					reg = <0xc000>;

					boost-bypass {
						function = "normal";
						linux,phandle = <0x42>;
						phandle = <0x42>;
						pins = "gpio21";
					};

					gpio-keys-active {
						bias-pull-up;
						function = "normal";
						linux,phandle = <0x3c>;
						phandle = <0x3c>;
						pins = "gpio2", "gpio3";
						power-source = <0x2>;
					};
				};

				iadc@3600 {
					compatible = "qcom,pm8941-iadc", "qcom,spmi-iadc";
					interrupts = <0x0 0x36 0x0 0x1>;
					linux,phandle = <0x69>;
					phandle = <0x69>;
					qcom,external-resistor-micro-ohms = <0x2710>;
					reg = <0x3600>;
				};

				misc@900 {
					compatible = "qcom,pm8941-misc";
					interrupt-names = "usb_id";
					interrupts = <0x0 0x9 0x0 0x3>;
					linux,phandle = <0x64>;
					phandle = <0x64>;
					reg = <0x900>;
				};

				mpps@a000 {
					#gpio-cells = <0x2>;
					compatible = "qcom,pm8941-mpp", "qcom,spmi-mpp";
					gpio-controller;
					interrupts = <0x0 0xa0 0x0 0x0 0x0 0xa1 0x0 0x0 0x0 0xa2 0x0 0x0 0x0 0xa3 0x0 0x0 0x0 0xa4 0x0 0x0 0x0 0xa5 0x0 0x0 0x0 0xa6 0x0 0x0 0x0 0xa7 0x0 0x0>;
					linux,phandle = <0x67>;
					phandle = <0x67>;
					reg = <0xa000>;
				};

				pwrkey@800 {
					bias-pull-up;
					compatible = "qcom,pm8941-pwrkey";
					debounce = <0x3d09>;
					interrupts = <0x0 0x8 0x0 0x3>;
					reg = <0x800>;
				};

				rtc@6000 {
					compatible = "qcom,pm8941-rtc";
					interrupts = <0x0 0x61 0x1 0x1>;
					reg = <0x6000 0x6100>;
					reg-names = "rtc", "alarm";
				};

				temp-alarm@2400 {
					#thermal-sensor-cells = <0x0>;
					compatible = "qcom,spmi-temp-alarm";
					interrupts = <0x0 0x24 0x0 0x1>;
					io-channel-names = "thermal";
					io-channels = <0x21 0x8>;
					linux,phandle = <0x68>;
					phandle = <0x68>;
					reg = <0x2400>;
				};

				vadc@3100 {
					#address-cells = <0x1>;
					#io-channel-cells = <0x1>;
					#size-cells = <0x0>;
					compatible = "qcom,spmi-vadc";
					interrupts = <0x0 0x31 0x0 0x1>;
					linux,phandle = <0x21>;
					phandle = <0x21>;
					reg = <0x3100>;

					die_temp {
						reg = <0x8>;
					};

					ref_1250v {
						reg = <0xa>;
					};

					ref_625mv {
						reg = <0x9>;
					};

					ref_gnd {
						reg = <0xe>;
					};

					ref_vdd {
						reg = <0xf>;
					};
				};
			};

			pm8941@1 {
				#address-cells = <0x1>;
				#size-cells = <0x0>;
				compatible = "qcom,pm8941", "qcom,spmi-pmic";
				linux,phandle = <0x6a>;
				phandle = <0x6a>;
				reg = <0x1 0x0>;

				regulators {
					compatible = "qcom,pm8941-regulators";
					interrupt-names = "ocp-5vs1", "ocp-5vs2";
					interrupts = <0x1 0x83 0x2 0x0 0x1 0x84 0x2 0x0>;
					vin_5vs-supply = <0x22>;

					5vs1 {
						linux,phandle = <0x20>;
						phandle = <0x20>;
						qcom,ocp-max-retries = <0xa>;
						qcom,ocp-retry-delay = <0x1e>;
						qcom,vs-soft-start-strength = <0x0>;
						regulator-enable-ramp-delay = <0x3e8>;
						regulator-initial-mode = <0x1>;
						regulator-over-current-protection;
						regulator-pull-down;
					};

					s4 {
						linux,phandle = <0x22>;
						phandle = <0x22>;
						regulator-enable-ramp-delay = <0x1f4>;
						regulator-max-microvolt = <0x4c4b40>;
						regulator-min-microvolt = <0x4c4b40>;
					};
				};

				wled@d800 {
					compatible = "qcom,pm8941-wled";
					label = "backlight";
					linux,phandle = <0x6b>;
					phandle = <0x6b>;
					reg = <0xd800>;
					status = "disabled";
				};
			};
		};

		syscon@f9011000 {
			compatible = "syscon";
			linux,phandle = <0x16>;
			phandle = <0x16>;
			reg = <0xf9011000 0x1000>;
		};

		syscon@fd484000 {
			compatible = "syscon";
			linux,phandle = <0x1a>;
			phandle = <0x1a>;
			reg = <0xfd484000 0x2000>;
		};

		syscon@fd4a0000 {
			compatible = "syscon";
			linux,phandle = <0x56>;
			phandle = <0x56>;
			reg = <0xfd4a0000 0x10000>;
		};

		tcsr-mutex {
			#hwlock-cells = <0x1>;
			compatible = "qcom,tcsr-mutex";
			linux,phandle = <0x15>;
			phandle = <0x15>;
			syscon = <0x1a 0x0 0x80>;
		};

		thermal-sensor@fc4a8000 {
			#thermal-sensor-cells = <0x1>;
			compatible = "qcom,msm8974-tsens";
			linux,phandle = <0xd>;
			nvmem-cell-names = "calib", "calib_backup";
			nvmem-cells = <0x18 0x19>;
			phandle = <0xd>;
			reg = <0xfc4a8000 0x2000>;
		};

		timer@f9020000 {
			#address-cells = <0x1>;
			#size-cells = <0x1>;
			clock-frequency = <0x124f800>;
			compatible = "arm,armv7-timer-mem";
			ranges;
			reg = <0xf9020000 0x1000>;

			frame@f9021000 {
				frame-number = <0x0>;
				interrupts = <0x0 0x8 0x4 0x0 0x7 0x4>;
				reg = <0xf9021000 0x1000 0xf9022000 0x1000>;
			};

			frame@f9023000 {
				frame-number = <0x1>;
				interrupts = <0x0 0x9 0x4>;
				reg = <0xf9023000 0x1000>;
				status = "disabled";
			};

			frame@f9024000 {
				frame-number = <0x2>;
				interrupts = <0x0 0xa 0x4>;
				reg = <0xf9024000 0x1000>;
				status = "disabled";
			};

			frame@f9025000 {
				frame-number = <0x3>;
				interrupts = <0x0 0xb 0x4>;
				reg = <0xf9025000 0x1000>;
				status = "disabled";
			};

			frame@f9026000 {
				frame-number = <0x4>;
				interrupts = <0x0 0xc 0x4>;
				reg = <0xf9026000 0x1000>;
				status = "disabled";
			};

			frame@f9027000 {
				frame-number = <0x5>;
				interrupts = <0x0 0xd 0x4>;
				reg = <0xf9027000 0x1000>;
				status = "disabled";
			};

			frame@f9028000 {
				frame-number = <0x6>;
				interrupts = <0x0 0xe 0x4>;
				reg = <0xf9028000 0x1000>;
				status = "disabled";
			};
		};

		tpiu@fc318000 {
			clock-names = "apb_pclk", "atclk";
			clocks = <0x23 0x8 0x23 0x9>;
			compatible = "arm,coresight-tpiu", "arm,primecell";
			reg = <0xfc318000 0x1000>;

			port {

				endpoint {
					linux,phandle = <0x27>;
					phandle = <0x27>;
					remote-endpoint = <0x25>;
					slave-mode;
				};
			};
		};

		usb@f9a55000 {
			#reset-cells = <0x1>;
			ahb-burst-config = <0x0>;
			assigned-clock-rates = <0x47868c0>;
			assigned-clocks = <0x17 0x109>;
			clock-names = "iface", "core";
			clocks = <0x17 0x107 0x17 0x109>;
			compatible = "qcom,ci-hdrc";
			dr_mode = "otg";
			interrupts = <0x0 0x86 0x4>;
			linux,phandle = <0x1e>;
			phandle = <0x1e>;
			phy-names = "usb-phy";
			phy_type = "ulpi";
			reg = <0xf9a55000 0x200 0xf9a55200 0x200>;
			reset-names = "core";
			resets = <0x17 0x9>;
			status = "disabled";

			ulpi {

				phy@a {
					#phy-cells = <0x0>;
					clock-names = "ref", "sleep";
					clocks = <0x10 0x17 0x102>;
					compatible = "qcom,usb-hs-phy-msm8974", "qcom,usb-hs-phy";
					linux,phandle = <0x5a>;
					phandle = <0x5a>;
					reset-names = "phy", "por";
					resets = <0x17 0xa 0x1e 0x0>;
					status = "disabled";
				};

				phy@b {
					#phy-cells = <0x0>;
					clock-names = "ref", "sleep";
					clocks = <0x10 0x17 0x103>;
					compatible = "qcom,usb-hs-phy-msm8974", "qcom,usb-hs-phy";
					linux,phandle = <0x5b>;
					phandle = <0x5b>;
					reset-names = "phy", "por";
					resets = <0x17 0xb 0x1e 0x1>;
					status = "disabled";
				};
			};
		};
	};

	thermal-zones {

		cpu-thermal0 {
			polling-delay = <0x3e8>;
			polling-delay-passive = <0xfa>;
			thermal-sensors = <0xd 0x5>;

			trips {

				trip0 {
					hysteresis = <0x7d0>;
					linux,phandle = <0x43>;
					phandle = <0x43>;
					temperature = <0x124f8>;
					type = "passive";
				};

				trip1 {
					hysteresis = <0x7d0>;
					linux,phandle = <0x44>;
					phandle = <0x44>;
					temperature = <0x1adb0>;
					type = "critical";
				};
			};
		};

		cpu-thermal1 {
			polling-delay = <0x3e8>;
			polling-delay-passive = <0xfa>;
			thermal-sensors = <0xd 0x6>;

			trips {

				trip0 {
					hysteresis = <0x7d0>;
					linux,phandle = <0x45>;
					phandle = <0x45>;
					temperature = <0x124f8>;
					type = "passive";
				};

				trip1 {
					hysteresis = <0x7d0>;
					linux,phandle = <0x46>;
					phandle = <0x46>;
					temperature = <0x1adb0>;
					type = "critical";
				};
			};
		};

		cpu-thermal2 {
			polling-delay = <0x3e8>;
			polling-delay-passive = <0xfa>;
			thermal-sensors = <0xd 0x7>;

			trips {

				trip0 {
					hysteresis = <0x7d0>;
					linux,phandle = <0x47>;
					phandle = <0x47>;
					temperature = <0x124f8>;
					type = "passive";
				};

				trip1 {
					hysteresis = <0x7d0>;
					linux,phandle = <0x48>;
					phandle = <0x48>;
					temperature = <0x1adb0>;
					type = "critical";
				};
			};
		};

		cpu-thermal3 {
			polling-delay = <0x3e8>;
			polling-delay-passive = <0xfa>;
			thermal-sensors = <0xd 0x8>;

			trips {

				trip0 {
					hysteresis = <0x7d0>;
					linux,phandle = <0x49>;
					phandle = <0x49>;
					temperature = <0x124f8>;
					type = "passive";
				};

				trip1 {
					hysteresis = <0x7d0>;
					linux,phandle = <0x4a>;
					phandle = <0x4a>;
					temperature = <0x1adb0>;
					type = "critical";
				};
			};
		};
	};

	timer {
		clock-frequency = <0x124f800>;
		compatible = "arm,armv7-timer";
		interrupts = <0x1 0x2 0xf08 0x1 0x3 0xf08 0x1 0x4 0xf08 0x1 0x1 0xf08>;
	};

	vreg-boost {
		compatible = "regulator-fixed";
		enable-active-high;
		gpio = <0x3d 0x15 0x0>;
		linux,phandle = <0x41>;
		phandle = <0x41>;
		pinctrl-0 = <0x42>;
		pinctrl-names = "default";
		regulator-always-on;
		regulator-boot-on;
		regulator-max-microvolt = <0x3010b0>;
		regulator-min-microvolt = <0x3010b0>;
		regulator-name = "vreg-boost";
	};

	vreg-vph-pwr {
		compatible = "regulator-fixed";
		linux,phandle = <0x40>;
		phandle = <0x40>;
		regulator-always-on;
		regulator-max-microvolt = <0x36ee80>;
		regulator-min-microvolt = <0x36ee80>;
		regulator-name = "vph-pwr";
	};
};
